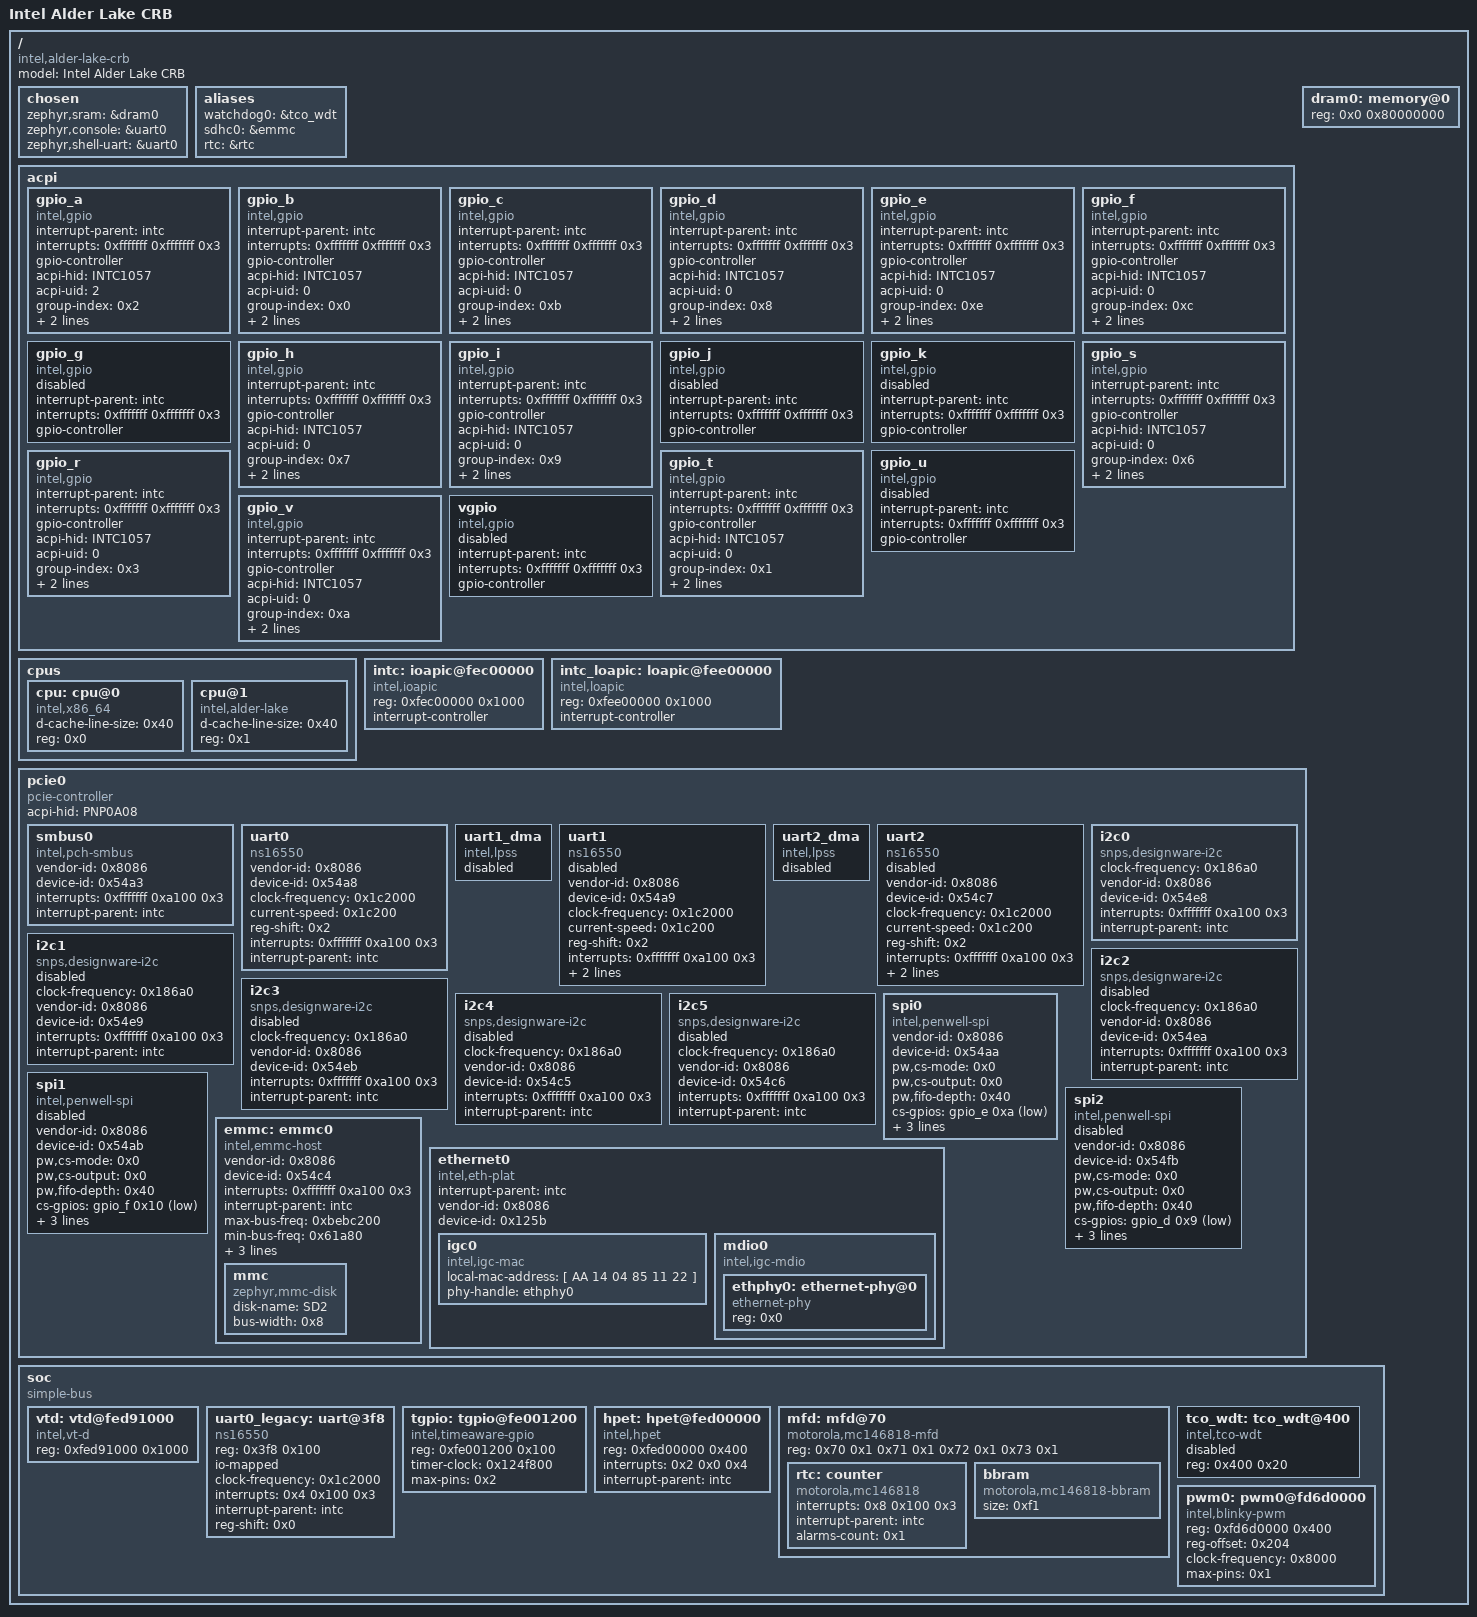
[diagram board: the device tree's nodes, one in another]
/dts-v1/;

/* node '/' defined in zephyr/dts/common/skeleton.dtsi:9 */
/ {
	#address-cells = < 0x1 >;            /* in zephyr/dts/common/skeleton.dtsi:10 */
	#size-cells = < 0x1 >;               /* in zephyr/dts/common/skeleton.dtsi:11 */
	model = "Intel Alder Lake CRB";      /* in zephyr/boards/intel/adl/intel_adl_crb.dts:10 */
	compatible = "intel,alder-lake-crb"; /* in zephyr/boards/intel/adl/intel_adl_crb.dts:11 */

	/* node '/chosen' defined in zephyr/dts/common/skeleton.dtsi:13 */
	chosen {
		zephyr,sram = &dram0;       /* in zephyr/boards/intel/adl/intel_adl.dts:17 */
		zephyr,console = &uart0;    /* in zephyr/boards/intel/adl/intel_adl_crb.dts:14 */
		zephyr,shell-uart = &uart0; /* in zephyr/boards/intel/adl/intel_adl_crb.dts:15 */
	};

	/* node '/aliases' defined in zephyr/dts/common/skeleton.dtsi:15 */
	aliases {
		watchdog0 = &tco_wdt; /* in zephyr/boards/intel/adl/intel_adl.dts:21 */
		sdhc0 = &emmc;        /* in zephyr/boards/intel/adl/intel_adl.dts:22 */
		rtc = &rtc;           /* in zephyr/boards/intel/adl/intel_adl_crb.dts:19 */
	};

	/* node '/acpi' defined in zephyr/dts/x86/intel/gpio_common.dtsi:12 */
	acpi {

		/* node '/acpi/gpio_a' defined in zephyr/dts/x86/intel/gpio_common.dtsi:13 */
		gpio_a: gpio_a {
			compatible = "intel,gpio";                /* in zephyr/dts/x86/intel/gpio_common.dtsi:14 */
			interrupt-parent = < &intc >;             /* in zephyr/dts/x86/intel/gpio_common.dtsi:15 */
			interrupts = < 0xfffffff 0xfffffff 0x3 >; /* in zephyr/dts/x86/intel/gpio_common.dtsi:16 */
			gpio-controller;                          /* in zephyr/dts/x86/intel/gpio_common.dtsi:17 */
			#gpio-cells = < 0x2 >;                    /* in zephyr/dts/x86/intel/gpio_common.dtsi:18 */
			acpi-hid = "INTC1057";                    /* in zephyr/dts/x86/intel/alder_lake.dtsi:57 */
			acpi-uid = "2";                           /* in zephyr/dts/x86/intel/alder_lake.dtsi:58 */
			group-index = < 0x2 >;                    /* in zephyr/dts/x86/intel/alder_lake.dtsi:59 */
			int-stat-offset = < 0x40 >;               /* in zephyr/dts/x86/intel/alder_lake.dtsi:60 */
			int-en-offset = < 0x20 >;                 /* in zephyr/dts/x86/intel/alder_lake.dtsi:61 */
			status = "okay";                          /* in zephyr/dts/x86/intel/alder_lake.dtsi:62 */
		};

		/* node '/acpi/gpio_b' defined in zephyr/dts/x86/intel/gpio_common.dtsi:22 */
		gpio_b: gpio_b {
			compatible = "intel,gpio";                /* in zephyr/dts/x86/intel/gpio_common.dtsi:23 */
			interrupt-parent = < &intc >;             /* in zephyr/dts/x86/intel/gpio_common.dtsi:24 */
			interrupts = < 0xfffffff 0xfffffff 0x3 >; /* in zephyr/dts/x86/intel/gpio_common.dtsi:25 */
			gpio-controller;                          /* in zephyr/dts/x86/intel/gpio_common.dtsi:26 */
			#gpio-cells = < 0x2 >;                    /* in zephyr/dts/x86/intel/gpio_common.dtsi:27 */
			acpi-hid = "INTC1057";                    /* in zephyr/dts/x86/intel/alder_lake.dtsi:66 */
			acpi-uid = "0";                           /* in zephyr/dts/x86/intel/alder_lake.dtsi:67 */
			group-index = < 0x0 >;                    /* in zephyr/dts/x86/intel/alder_lake.dtsi:68 */
			int-stat-offset = < 0x40 >;               /* in zephyr/dts/x86/intel/alder_lake.dtsi:69 */
			int-en-offset = < 0x20 >;                 /* in zephyr/dts/x86/intel/alder_lake.dtsi:70 */
			status = "okay";                          /* in zephyr/dts/x86/intel/alder_lake.dtsi:71 */
		};

		/* node '/acpi/gpio_c' defined in zephyr/dts/x86/intel/gpio_common.dtsi:31 */
		gpio_c: gpio_c {
			compatible = "intel,gpio";                /* in zephyr/dts/x86/intel/gpio_common.dtsi:32 */
			interrupt-parent = < &intc >;             /* in zephyr/dts/x86/intel/gpio_common.dtsi:33 */
			interrupts = < 0xfffffff 0xfffffff 0x3 >; /* in zephyr/dts/x86/intel/gpio_common.dtsi:34 */
			gpio-controller;                          /* in zephyr/dts/x86/intel/gpio_common.dtsi:35 */
			#gpio-cells = < 0x2 >;                    /* in zephyr/dts/x86/intel/gpio_common.dtsi:36 */
			acpi-hid = "INTC1057";                    /* in zephyr/dts/x86/intel/alder_lake.dtsi:75 */
			acpi-uid = "0";                           /* in zephyr/dts/x86/intel/alder_lake.dtsi:76 */
			group-index = < 0xb >;                    /* in zephyr/dts/x86/intel/alder_lake.dtsi:77 */
			int-stat-offset = < 0x40 >;               /* in zephyr/dts/x86/intel/alder_lake.dtsi:78 */
			int-en-offset = < 0x20 >;                 /* in zephyr/dts/x86/intel/alder_lake.dtsi:79 */
			status = "okay";                          /* in zephyr/dts/x86/intel/alder_lake.dtsi:80 */
		};

		/* node '/acpi/gpio_d' defined in zephyr/dts/x86/intel/gpio_common.dtsi:40 */
		gpio_d: gpio_d {
			compatible = "intel,gpio";                /* in zephyr/dts/x86/intel/gpio_common.dtsi:41 */
			interrupt-parent = < &intc >;             /* in zephyr/dts/x86/intel/gpio_common.dtsi:42 */
			interrupts = < 0xfffffff 0xfffffff 0x3 >; /* in zephyr/dts/x86/intel/gpio_common.dtsi:43 */
			gpio-controller;                          /* in zephyr/dts/x86/intel/gpio_common.dtsi:44 */
			#gpio-cells = < 0x2 >;                    /* in zephyr/dts/x86/intel/gpio_common.dtsi:45 */
			acpi-hid = "INTC1057";                    /* in zephyr/dts/x86/intel/alder_lake.dtsi:84 */
			acpi-uid = "0";                           /* in zephyr/dts/x86/intel/alder_lake.dtsi:85 */
			group-index = < 0x8 >;                    /* in zephyr/dts/x86/intel/alder_lake.dtsi:86 */
			int-stat-offset = < 0x40 >;               /* in zephyr/dts/x86/intel/alder_lake.dtsi:87 */
			int-en-offset = < 0x20 >;                 /* in zephyr/dts/x86/intel/alder_lake.dtsi:88 */
			status = "okay";                          /* in zephyr/dts/x86/intel/alder_lake.dtsi:89 */
			phandle = < 0x6 >;                        /* in zephyr/dts/x86/intel/alder_lake.dtsi:359 */
		};

		/* node '/acpi/gpio_e' defined in zephyr/dts/x86/intel/gpio_common.dtsi:49 */
		gpio_e: gpio_e {
			compatible = "intel,gpio";                /* in zephyr/dts/x86/intel/gpio_common.dtsi:50 */
			interrupt-parent = < &intc >;             /* in zephyr/dts/x86/intel/gpio_common.dtsi:51 */
			interrupts = < 0xfffffff 0xfffffff 0x3 >; /* in zephyr/dts/x86/intel/gpio_common.dtsi:52 */
			gpio-controller;                          /* in zephyr/dts/x86/intel/gpio_common.dtsi:53 */
			#gpio-cells = < 0x2 >;                    /* in zephyr/dts/x86/intel/gpio_common.dtsi:54 */
			acpi-hid = "INTC1057";                    /* in zephyr/dts/x86/intel/alder_lake.dtsi:93 */
			acpi-uid = "0";                           /* in zephyr/dts/x86/intel/alder_lake.dtsi:94 */
			group-index = < 0xe >;                    /* in zephyr/dts/x86/intel/alder_lake.dtsi:95 */
			int-stat-offset = < 0x40 >;               /* in zephyr/dts/x86/intel/alder_lake.dtsi:96 */
			int-en-offset = < 0x20 >;                 /* in zephyr/dts/x86/intel/alder_lake.dtsi:97 */
			status = "okay";                          /* in zephyr/dts/x86/intel/alder_lake.dtsi:98 */
			phandle = < 0x4 >;                        /* in zephyr/dts/x86/intel/alder_lake.dtsi:327 */
		};

		/* node '/acpi/gpio_f' defined in zephyr/dts/x86/intel/gpio_common.dtsi:58 */
		gpio_f: gpio_f {
			compatible = "intel,gpio";                /* in zephyr/dts/x86/intel/gpio_common.dtsi:59 */
			interrupt-parent = < &intc >;             /* in zephyr/dts/x86/intel/gpio_common.dtsi:60 */
			interrupts = < 0xfffffff 0xfffffff 0x3 >; /* in zephyr/dts/x86/intel/gpio_common.dtsi:61 */
			gpio-controller;                          /* in zephyr/dts/x86/intel/gpio_common.dtsi:62 */
			#gpio-cells = < 0x2 >;                    /* in zephyr/dts/x86/intel/gpio_common.dtsi:63 */
			acpi-hid = "INTC1057";                    /* in zephyr/dts/x86/intel/alder_lake.dtsi:102 */
			acpi-uid = "0";                           /* in zephyr/dts/x86/intel/alder_lake.dtsi:103 */
			group-index = < 0xc >;                    /* in zephyr/dts/x86/intel/alder_lake.dtsi:104 */
			int-stat-offset = < 0x40 >;               /* in zephyr/dts/x86/intel/alder_lake.dtsi:105 */
			int-en-offset = < 0x20 >;                 /* in zephyr/dts/x86/intel/alder_lake.dtsi:106 */
			status = "okay";                          /* in zephyr/dts/x86/intel/alder_lake.dtsi:107 */
			phandle = < 0x5 >;                        /* in zephyr/dts/x86/intel/alder_lake.dtsi:343 */
		};

		/* node '/acpi/gpio_g' defined in zephyr/dts/x86/intel/gpio_common.dtsi:67 */
		gpio_g: gpio_g {
			compatible = "intel,gpio";                /* in zephyr/dts/x86/intel/gpio_common.dtsi:68 */
			interrupt-parent = < &intc >;             /* in zephyr/dts/x86/intel/gpio_common.dtsi:69 */
			interrupts = < 0xfffffff 0xfffffff 0x3 >; /* in zephyr/dts/x86/intel/gpio_common.dtsi:70 */
			gpio-controller;                          /* in zephyr/dts/x86/intel/gpio_common.dtsi:71 */
			#gpio-cells = < 0x2 >;                    /* in zephyr/dts/x86/intel/gpio_common.dtsi:72 */
			status = "disabled";                      /* in zephyr/dts/x86/intel/gpio_common.dtsi:73 */
		};

		/* node '/acpi/gpio_h' defined in zephyr/dts/x86/intel/gpio_common.dtsi:76 */
		gpio_h: gpio_h {
			compatible = "intel,gpio";                /* in zephyr/dts/x86/intel/gpio_common.dtsi:77 */
			interrupt-parent = < &intc >;             /* in zephyr/dts/x86/intel/gpio_common.dtsi:78 */
			interrupts = < 0xfffffff 0xfffffff 0x3 >; /* in zephyr/dts/x86/intel/gpio_common.dtsi:79 */
			gpio-controller;                          /* in zephyr/dts/x86/intel/gpio_common.dtsi:80 */
			#gpio-cells = < 0x2 >;                    /* in zephyr/dts/x86/intel/gpio_common.dtsi:81 */
			acpi-hid = "INTC1057";                    /* in zephyr/dts/x86/intel/alder_lake.dtsi:111 */
			acpi-uid = "0";                           /* in zephyr/dts/x86/intel/alder_lake.dtsi:112 */
			group-index = < 0x7 >;                    /* in zephyr/dts/x86/intel/alder_lake.dtsi:113 */
			int-stat-offset = < 0x40 >;               /* in zephyr/dts/x86/intel/alder_lake.dtsi:114 */
			int-en-offset = < 0x20 >;                 /* in zephyr/dts/x86/intel/alder_lake.dtsi:115 */
			status = "okay";                          /* in zephyr/dts/x86/intel/alder_lake.dtsi:116 */
		};

		/* node '/acpi/gpio_i' defined in zephyr/dts/x86/intel/gpio_common.dtsi:85 */
		gpio_i: gpio_i {
			compatible = "intel,gpio";                /* in zephyr/dts/x86/intel/gpio_common.dtsi:86 */
			interrupt-parent = < &intc >;             /* in zephyr/dts/x86/intel/gpio_common.dtsi:87 */
			interrupts = < 0xfffffff 0xfffffff 0x3 >; /* in zephyr/dts/x86/intel/gpio_common.dtsi:88 */
			gpio-controller;                          /* in zephyr/dts/x86/intel/gpio_common.dtsi:89 */
			#gpio-cells = < 0x2 >;                    /* in zephyr/dts/x86/intel/gpio_common.dtsi:90 */
			acpi-hid = "INTC1057";                    /* in zephyr/dts/x86/intel/alder_lake.dtsi:120 */
			acpi-uid = "0";                           /* in zephyr/dts/x86/intel/alder_lake.dtsi:121 */
			group-index = < 0x9 >;                    /* in zephyr/dts/x86/intel/alder_lake.dtsi:122 */
			int-stat-offset = < 0x40 >;               /* in zephyr/dts/x86/intel/alder_lake.dtsi:123 */
			int-en-offset = < 0x20 >;                 /* in zephyr/dts/x86/intel/alder_lake.dtsi:124 */
			status = "okay";                          /* in zephyr/dts/x86/intel/alder_lake.dtsi:125 */
		};

		/* node '/acpi/gpio_j' defined in zephyr/dts/x86/intel/gpio_common.dtsi:94 */
		gpio_j: gpio_j {
			compatible = "intel,gpio";                /* in zephyr/dts/x86/intel/gpio_common.dtsi:95 */
			interrupt-parent = < &intc >;             /* in zephyr/dts/x86/intel/gpio_common.dtsi:96 */
			interrupts = < 0xfffffff 0xfffffff 0x3 >; /* in zephyr/dts/x86/intel/gpio_common.dtsi:97 */
			gpio-controller;                          /* in zephyr/dts/x86/intel/gpio_common.dtsi:98 */
			#gpio-cells = < 0x2 >;                    /* in zephyr/dts/x86/intel/gpio_common.dtsi:99 */
			status = "disabled";                      /* in zephyr/dts/x86/intel/gpio_common.dtsi:100 */
		};

		/* node '/acpi/gpio_k' defined in zephyr/dts/x86/intel/gpio_common.dtsi:103 */
		gpio_k: gpio_k {
			compatible = "intel,gpio";                /* in zephyr/dts/x86/intel/gpio_common.dtsi:104 */
			interrupt-parent = < &intc >;             /* in zephyr/dts/x86/intel/gpio_common.dtsi:105 */
			interrupts = < 0xfffffff 0xfffffff 0x3 >; /* in zephyr/dts/x86/intel/gpio_common.dtsi:106 */
			gpio-controller;                          /* in zephyr/dts/x86/intel/gpio_common.dtsi:107 */
			#gpio-cells = < 0x2 >;                    /* in zephyr/dts/x86/intel/gpio_common.dtsi:108 */
			status = "disabled";                      /* in zephyr/dts/x86/intel/gpio_common.dtsi:109 */
		};

		/* node '/acpi/gpio_s' defined in zephyr/dts/x86/intel/gpio_common.dtsi:112 */
		gpio_s: gpio_s {
			compatible = "intel,gpio";                /* in zephyr/dts/x86/intel/gpio_common.dtsi:113 */
			interrupt-parent = < &intc >;             /* in zephyr/dts/x86/intel/gpio_common.dtsi:114 */
			interrupts = < 0xfffffff 0xfffffff 0x3 >; /* in zephyr/dts/x86/intel/gpio_common.dtsi:115 */
			gpio-controller;                          /* in zephyr/dts/x86/intel/gpio_common.dtsi:116 */
			#gpio-cells = < 0x2 >;                    /* in zephyr/dts/x86/intel/gpio_common.dtsi:117 */
			acpi-hid = "INTC1057";                    /* in zephyr/dts/x86/intel/alder_lake.dtsi:129 */
			acpi-uid = "0";                           /* in zephyr/dts/x86/intel/alder_lake.dtsi:130 */
			group-index = < 0x6 >;                    /* in zephyr/dts/x86/intel/alder_lake.dtsi:131 */
			int-stat-offset = < 0x40 >;               /* in zephyr/dts/x86/intel/alder_lake.dtsi:132 */
			int-en-offset = < 0x20 >;                 /* in zephyr/dts/x86/intel/alder_lake.dtsi:133 */
			status = "okay";                          /* in zephyr/dts/x86/intel/alder_lake.dtsi:134 */
		};

		/* node '/acpi/gpio_r' defined in zephyr/dts/x86/intel/gpio_common.dtsi:121 */
		gpio_r: gpio_r {
			compatible = "intel,gpio";                /* in zephyr/dts/x86/intel/gpio_common.dtsi:122 */
			interrupt-parent = < &intc >;             /* in zephyr/dts/x86/intel/gpio_common.dtsi:123 */
			interrupts = < 0xfffffff 0xfffffff 0x3 >; /* in zephyr/dts/x86/intel/gpio_common.dtsi:124 */
			gpio-controller;                          /* in zephyr/dts/x86/intel/gpio_common.dtsi:125 */
			#gpio-cells = < 0x2 >;                    /* in zephyr/dts/x86/intel/gpio_common.dtsi:126 */
			acpi-hid = "INTC1057";                    /* in zephyr/dts/x86/intel/alder_lake.dtsi:138 */
			acpi-uid = "0";                           /* in zephyr/dts/x86/intel/alder_lake.dtsi:139 */
			group-index = < 0x3 >;                    /* in zephyr/dts/x86/intel/alder_lake.dtsi:140 */
			int-stat-offset = < 0x40 >;               /* in zephyr/dts/x86/intel/alder_lake.dtsi:141 */
			int-en-offset = < 0x20 >;                 /* in zephyr/dts/x86/intel/alder_lake.dtsi:142 */
			status = "okay";                          /* in zephyr/dts/x86/intel/alder_lake.dtsi:143 */
		};

		/* node '/acpi/gpio_t' defined in zephyr/dts/x86/intel/gpio_common.dtsi:130 */
		gpio_t: gpio_t {
			compatible = "intel,gpio";                /* in zephyr/dts/x86/intel/gpio_common.dtsi:131 */
			interrupt-parent = < &intc >;             /* in zephyr/dts/x86/intel/gpio_common.dtsi:132 */
			interrupts = < 0xfffffff 0xfffffff 0x3 >; /* in zephyr/dts/x86/intel/gpio_common.dtsi:133 */
			gpio-controller;                          /* in zephyr/dts/x86/intel/gpio_common.dtsi:134 */
			#gpio-cells = < 0x2 >;                    /* in zephyr/dts/x86/intel/gpio_common.dtsi:135 */
			acpi-hid = "INTC1057";                    /* in zephyr/dts/x86/intel/alder_lake.dtsi:147 */
			acpi-uid = "0";                           /* in zephyr/dts/x86/intel/alder_lake.dtsi:148 */
			group-index = < 0x1 >;                    /* in zephyr/dts/x86/intel/alder_lake.dtsi:149 */
			int-stat-offset = < 0x40 >;               /* in zephyr/dts/x86/intel/alder_lake.dtsi:150 */
			int-en-offset = < 0x20 >;                 /* in zephyr/dts/x86/intel/alder_lake.dtsi:151 */
			status = "okay";                          /* in zephyr/dts/x86/intel/alder_lake.dtsi:152 */
		};

		/* node '/acpi/gpio_u' defined in zephyr/dts/x86/intel/gpio_common.dtsi:139 */
		gpio_u: gpio_u {
			compatible = "intel,gpio";                /* in zephyr/dts/x86/intel/gpio_common.dtsi:140 */
			interrupt-parent = < &intc >;             /* in zephyr/dts/x86/intel/gpio_common.dtsi:141 */
			interrupts = < 0xfffffff 0xfffffff 0x3 >; /* in zephyr/dts/x86/intel/gpio_common.dtsi:142 */
			gpio-controller;                          /* in zephyr/dts/x86/intel/gpio_common.dtsi:143 */
			#gpio-cells = < 0x2 >;                    /* in zephyr/dts/x86/intel/gpio_common.dtsi:144 */
			status = "disabled";                      /* in zephyr/dts/x86/intel/gpio_common.dtsi:145 */
		};

		/* node '/acpi/gpio_v' defined in zephyr/dts/x86/intel/gpio_common.dtsi:148 */
		gpio_v: gpio_v {
			compatible = "intel,gpio";                /* in zephyr/dts/x86/intel/gpio_common.dtsi:149 */
			interrupt-parent = < &intc >;             /* in zephyr/dts/x86/intel/gpio_common.dtsi:150 */
			interrupts = < 0xfffffff 0xfffffff 0x3 >; /* in zephyr/dts/x86/intel/gpio_common.dtsi:151 */
			gpio-controller;                          /* in zephyr/dts/x86/intel/gpio_common.dtsi:152 */
			#gpio-cells = < 0x2 >;                    /* in zephyr/dts/x86/intel/gpio_common.dtsi:153 */
			acpi-hid = "INTC1057";                    /* in zephyr/dts/x86/intel/alder_lake.dtsi:156 */
			acpi-uid = "0";                           /* in zephyr/dts/x86/intel/alder_lake.dtsi:157 */
			group-index = < 0xa >;                    /* in zephyr/dts/x86/intel/alder_lake.dtsi:158 */
			int-stat-offset = < 0x40 >;               /* in zephyr/dts/x86/intel/alder_lake.dtsi:159 */
			int-en-offset = < 0x20 >;                 /* in zephyr/dts/x86/intel/alder_lake.dtsi:160 */
			status = "okay";                          /* in zephyr/dts/x86/intel/alder_lake.dtsi:161 */
		};

		/* node '/acpi/vgpio' defined in zephyr/dts/x86/intel/gpio_common.dtsi:157 */
		vgpio: vgpio {
			compatible = "intel,gpio";                /* in zephyr/dts/x86/intel/gpio_common.dtsi:158 */
			interrupt-parent = < &intc >;             /* in zephyr/dts/x86/intel/gpio_common.dtsi:159 */
			interrupts = < 0xfffffff 0xfffffff 0x3 >; /* in zephyr/dts/x86/intel/gpio_common.dtsi:160 */
			gpio-controller;                          /* in zephyr/dts/x86/intel/gpio_common.dtsi:161 */
			#gpio-cells = < 0x2 >;                    /* in zephyr/dts/x86/intel/gpio_common.dtsi:162 */
			status = "disabled";                      /* in zephyr/dts/x86/intel/gpio_common.dtsi:163 */
		};
	};

	/* node '/cpus' defined in zephyr/dts/x86/intel/alder_lake.dtsi:15 */
	cpus {
		#address-cells = < 0x1 >; /* in zephyr/dts/x86/intel/alder_lake.dtsi:16 */
		#size-cells = < 0x0 >;    /* in zephyr/dts/x86/intel/alder_lake.dtsi:17 */

		/* node '/cpus/cpu@0' defined in zephyr/dts/x86/intel/alder_lake.dtsi:19 */
		cpu: cpu@0 {
			device_type = "cpu";          /* in zephyr/dts/x86/intel/alder_lake.dtsi:20 */
			d-cache-line-size = < 0x40 >; /* in zephyr/dts/x86/intel/alder_lake.dtsi:22 */
			reg = < 0x0 >;                /* in zephyr/dts/x86/intel/alder_lake.dtsi:23 */
			compatible = "intel,x86_64";  /* in zephyr/boards/intel/adl/intel_adl.dts:27 */
		};

		/* node '/cpus/cpu@1' defined in zephyr/dts/x86/intel/alder_lake.dtsi:26 */
		cpu@1 {
			device_type = "cpu";             /* in zephyr/dts/x86/intel/alder_lake.dtsi:27 */
			compatible = "intel,alder-lake",
			             "intel,x86_64";     /* in zephyr/dts/x86/intel/alder_lake.dtsi:28 */
			d-cache-line-size = < 0x40 >;    /* in zephyr/dts/x86/intel/alder_lake.dtsi:29 */
			reg = < 0x1 >;                   /* in zephyr/dts/x86/intel/alder_lake.dtsi:30 */
		};
	};

	/* node '/memory@0' defined in zephyr/dts/x86/intel/alder_lake.dtsi:34 */
	dram0: memory@0 {
		device_type = "memory";   /* in zephyr/dts/x86/intel/alder_lake.dtsi:35 */
		reg = < 0x0 0x80000000 >; /* in zephyr/dts/x86/intel/alder_lake.dtsi:36 */
	};

	/* node '/ioapic@fec00000' defined in zephyr/dts/x86/intel/alder_lake.dtsi:39 */
	intc: ioapic@fec00000 {
		compatible = "intel,ioapic"; /* in zephyr/dts/x86/intel/alder_lake.dtsi:40 */
		#address-cells = < 0x1 >;    /* in zephyr/dts/x86/intel/alder_lake.dtsi:41 */
		#interrupt-cells = < 0x3 >;  /* in zephyr/dts/x86/intel/alder_lake.dtsi:42 */
		reg = < 0xfec00000 0x1000 >; /* in zephyr/dts/x86/intel/alder_lake.dtsi:43 */
		interrupt-controller;        /* in zephyr/dts/x86/intel/alder_lake.dtsi:44 */
		phandle = < 0x1 >;           /* in zephyr/dts/x86/intel/gpio_common.dtsi:15 */
	};

	/* node '/loapic@fee00000' defined in zephyr/dts/x86/intel/alder_lake.dtsi:47 */
	intc_loapic: loapic@fee00000 {
		compatible = "intel,loapic"; /* in zephyr/dts/x86/intel/alder_lake.dtsi:48 */
		reg = < 0xfee00000 0x1000 >; /* in zephyr/dts/x86/intel/alder_lake.dtsi:49 */
		interrupt-controller;        /* in zephyr/dts/x86/intel/alder_lake.dtsi:50 */
		#interrupt-cells = < 0x3 >;  /* in zephyr/dts/x86/intel/alder_lake.dtsi:51 */
		#address-cells = < 0x1 >;    /* in zephyr/dts/x86/intel/alder_lake.dtsi:52 */
	};

	/* node '/pcie0' defined in zephyr/dts/x86/intel/alder_lake.dtsi:165 */
	pcie0: pcie0 {
		#address-cells = < 0x1 >;       /* in zephyr/dts/x86/intel/alder_lake.dtsi:166 */
		#size-cells = < 0x1 >;          /* in zephyr/dts/x86/intel/alder_lake.dtsi:167 */
		compatible = "pcie-controller"; /* in zephyr/dts/x86/intel/alder_lake.dtsi:168 */
		acpi-hid = "PNP0A08";           /* in zephyr/dts/x86/intel/alder_lake.dtsi:169 */
		ranges;                         /* in zephyr/dts/x86/intel/alder_lake.dtsi:170 */

		/* node '/pcie0/smbus0' defined in zephyr/dts/x86/intel/alder_lake.dtsi:172 */
		smbus0: smbus0 {
			compatible = "intel,pch-smbus";        /* in zephyr/dts/x86/intel/alder_lake.dtsi:173 */
			#address-cells = < 0x1 >;              /* in zephyr/dts/x86/intel/alder_lake.dtsi:174 */
			#size-cells = < 0x0 >;                 /* in zephyr/dts/x86/intel/alder_lake.dtsi:175 */
			vendor-id = < 0x8086 >;                /* in zephyr/dts/x86/intel/alder_lake.dtsi:176 */
			device-id = < 0x54a3 >;                /* in zephyr/dts/x86/intel/alder_lake.dtsi:177 */
			interrupts = < 0xfffffff 0xa100 0x3 >; /* in zephyr/dts/x86/intel/alder_lake.dtsi:178 */
			interrupt-parent = < &intc >;          /* in zephyr/dts/x86/intel/alder_lake.dtsi:179 */
			status = "okay";                       /* in zephyr/dts/x86/intel/alder_lake.dtsi:181 */
		};

		/* node '/pcie0/uart0' defined in zephyr/dts/x86/intel/alder_lake.dtsi:184 */
		uart0: uart0 {
			compatible = "ns16550";                /* in zephyr/dts/x86/intel/alder_lake.dtsi:185 */
			vendor-id = < 0x8086 >;                /* in zephyr/dts/x86/intel/alder_lake.dtsi:187 */
			device-id = < 0x54a8 >;                /* in zephyr/dts/x86/intel/alder_lake.dtsi:188 */
			clock-frequency = < 0x1c2000 >;        /* in zephyr/dts/x86/intel/alder_lake.dtsi:190 */
			current-speed = < 0x1c200 >;           /* in zephyr/dts/x86/intel/alder_lake.dtsi:191 */
			reg-shift = < 0x2 >;                   /* in zephyr/dts/x86/intel/alder_lake.dtsi:192 */
			interrupts = < 0xfffffff 0xa100 0x3 >; /* in zephyr/dts/x86/intel/alder_lake.dtsi:194 */
			interrupt-parent = < &intc >;          /* in zephyr/dts/x86/intel/alder_lake.dtsi:195 */
			status = "okay";                       /* in zephyr/boards/intel/adl/intel_adl_crb.dts:24 */
		};

		/* node '/pcie0/uart1_dma' defined in zephyr/dts/x86/intel/alder_lake.dtsi:199 */
		uart1_dma: uart1_dma {
			compatible = "intel,lpss"; /* in zephyr/dts/x86/intel/alder_lake.dtsi:200 */
			#dma-cells = < 0x1 >;      /* in zephyr/dts/x86/intel/alder_lake.dtsi:201 */
			status = "disabled";       /* in zephyr/dts/x86/intel/alder_lake.dtsi:202 */
			phandle = < 0x2 >;         /* in zephyr/dts/x86/intel/alder_lake.dtsi:214 */
		};

		/* node '/pcie0/uart1' defined in zephyr/dts/x86/intel/alder_lake.dtsi:205 */
		uart1: uart1 {
			compatible = "ns16550";                /* in zephyr/dts/x86/intel/alder_lake.dtsi:206 */
			vendor-id = < 0x8086 >;                /* in zephyr/dts/x86/intel/alder_lake.dtsi:207 */
			device-id = < 0x54a9 >;                /* in zephyr/dts/x86/intel/alder_lake.dtsi:208 */
			clock-frequency = < 0x1c2000 >;        /* in zephyr/dts/x86/intel/alder_lake.dtsi:209 */
			current-speed = < 0x1c200 >;           /* in zephyr/dts/x86/intel/alder_lake.dtsi:210 */
			reg-shift = < 0x2 >;                   /* in zephyr/dts/x86/intel/alder_lake.dtsi:211 */
			interrupts = < 0xfffffff 0xa100 0x3 >; /* in zephyr/dts/x86/intel/alder_lake.dtsi:212 */
			interrupt-parent = < &intc >;          /* in zephyr/dts/x86/intel/alder_lake.dtsi:213 */
			dmas = < &uart1_dma 0x0 >,
			       < &uart1_dma 0x1 >;             /* in zephyr/dts/x86/intel/alder_lake.dtsi:214 */
			dma-names = "tx",
			            "rx";                      /* in zephyr/dts/x86/intel/alder_lake.dtsi:215 */
			status = "disabled";                   /* in zephyr/dts/x86/intel/alder_lake.dtsi:216 */
		};

		/* node '/pcie0/uart2_dma' defined in zephyr/dts/x86/intel/alder_lake.dtsi:219 */
		uart2_dma: uart2_dma {
			compatible = "intel,lpss"; /* in zephyr/dts/x86/intel/alder_lake.dtsi:220 */
			#dma-cells = < 0x1 >;      /* in zephyr/dts/x86/intel/alder_lake.dtsi:221 */
			status = "disabled";       /* in zephyr/dts/x86/intel/alder_lake.dtsi:222 */
			phandle = < 0x3 >;         /* in zephyr/dts/x86/intel/alder_lake.dtsi:234 */
		};

		/* node '/pcie0/uart2' defined in zephyr/dts/x86/intel/alder_lake.dtsi:225 */
		uart2: uart2 {
			compatible = "ns16550";                /* in zephyr/dts/x86/intel/alder_lake.dtsi:226 */
			vendor-id = < 0x8086 >;                /* in zephyr/dts/x86/intel/alder_lake.dtsi:227 */
			device-id = < 0x54c7 >;                /* in zephyr/dts/x86/intel/alder_lake.dtsi:228 */
			clock-frequency = < 0x1c2000 >;        /* in zephyr/dts/x86/intel/alder_lake.dtsi:229 */
			current-speed = < 0x1c200 >;           /* in zephyr/dts/x86/intel/alder_lake.dtsi:230 */
			reg-shift = < 0x2 >;                   /* in zephyr/dts/x86/intel/alder_lake.dtsi:231 */
			interrupts = < 0xfffffff 0xa100 0x3 >; /* in zephyr/dts/x86/intel/alder_lake.dtsi:232 */
			interrupt-parent = < &intc >;          /* in zephyr/dts/x86/intel/alder_lake.dtsi:233 */
			dmas = < &uart2_dma 0x0 >,
			       < &uart2_dma 0x1 >;             /* in zephyr/dts/x86/intel/alder_lake.dtsi:234 */
			dma-names = "tx",
			            "rx";                      /* in zephyr/dts/x86/intel/alder_lake.dtsi:235 */
			status = "disabled";                   /* in zephyr/dts/x86/intel/alder_lake.dtsi:237 */
		};

		/* node '/pcie0/i2c0' defined in zephyr/dts/x86/intel/alder_lake.dtsi:240 */
		i2c0: i2c0 {
			compatible = "snps,designware-i2c";    /* in zephyr/dts/x86/intel/alder_lake.dtsi:241 */
			clock-frequency = < 0x186a0 >;         /* in zephyr/dts/x86/intel/alder_lake.dtsi:242 */
			#address-cells = < 0x1 >;              /* in zephyr/dts/x86/intel/alder_lake.dtsi:243 */
			#size-cells = < 0x0 >;                 /* in zephyr/dts/x86/intel/alder_lake.dtsi:244 */
			vendor-id = < 0x8086 >;                /* in zephyr/dts/x86/intel/alder_lake.dtsi:245 */
			device-id = < 0x54e8 >;                /* in zephyr/dts/x86/intel/alder_lake.dtsi:246 */
			interrupts = < 0xfffffff 0xa100 0x3 >; /* in zephyr/dts/x86/intel/alder_lake.dtsi:247 */
			interrupt-parent = < &intc >;          /* in zephyr/dts/x86/intel/alder_lake.dtsi:248 */
			status = "okay";                       /* in zephyr/dts/x86/intel/alder_lake.dtsi:250 */
		};

		/* node '/pcie0/i2c1' defined in zephyr/dts/x86/intel/alder_lake.dtsi:253 */
		i2c1: i2c1 {
			compatible = "snps,designware-i2c";    /* in zephyr/dts/x86/intel/alder_lake.dtsi:254 */
			clock-frequency = < 0x186a0 >;         /* in zephyr/dts/x86/intel/alder_lake.dtsi:255 */
			#address-cells = < 0x1 >;              /* in zephyr/dts/x86/intel/alder_lake.dtsi:256 */
			#size-cells = < 0x0 >;                 /* in zephyr/dts/x86/intel/alder_lake.dtsi:257 */
			vendor-id = < 0x8086 >;                /* in zephyr/dts/x86/intel/alder_lake.dtsi:258 */
			device-id = < 0x54e9 >;                /* in zephyr/dts/x86/intel/alder_lake.dtsi:259 */
			interrupts = < 0xfffffff 0xa100 0x3 >; /* in zephyr/dts/x86/intel/alder_lake.dtsi:260 */
			interrupt-parent = < &intc >;          /* in zephyr/dts/x86/intel/alder_lake.dtsi:261 */
			status = "disabled";                   /* in zephyr/dts/x86/intel/alder_lake.dtsi:263 */
		};

		/* node '/pcie0/i2c2' defined in zephyr/dts/x86/intel/alder_lake.dtsi:266 */
		i2c2: i2c2 {
			compatible = "snps,designware-i2c";    /* in zephyr/dts/x86/intel/alder_lake.dtsi:267 */
			clock-frequency = < 0x186a0 >;         /* in zephyr/dts/x86/intel/alder_lake.dtsi:268 */
			#address-cells = < 0x1 >;              /* in zephyr/dts/x86/intel/alder_lake.dtsi:269 */
			#size-cells = < 0x0 >;                 /* in zephyr/dts/x86/intel/alder_lake.dtsi:270 */
			vendor-id = < 0x8086 >;                /* in zephyr/dts/x86/intel/alder_lake.dtsi:271 */
			device-id = < 0x54ea >;                /* in zephyr/dts/x86/intel/alder_lake.dtsi:272 */
			interrupts = < 0xfffffff 0xa100 0x3 >; /* in zephyr/dts/x86/intel/alder_lake.dtsi:273 */
			interrupt-parent = < &intc >;          /* in zephyr/dts/x86/intel/alder_lake.dtsi:274 */
			status = "disabled";                   /* in zephyr/dts/x86/intel/alder_lake.dtsi:276 */
		};

		/* node '/pcie0/i2c3' defined in zephyr/dts/x86/intel/alder_lake.dtsi:279 */
		i2c3: i2c3 {
			compatible = "snps,designware-i2c";    /* in zephyr/dts/x86/intel/alder_lake.dtsi:280 */
			clock-frequency = < 0x186a0 >;         /* in zephyr/dts/x86/intel/alder_lake.dtsi:281 */
			#address-cells = < 0x1 >;              /* in zephyr/dts/x86/intel/alder_lake.dtsi:282 */
			#size-cells = < 0x0 >;                 /* in zephyr/dts/x86/intel/alder_lake.dtsi:283 */
			vendor-id = < 0x8086 >;                /* in zephyr/dts/x86/intel/alder_lake.dtsi:284 */
			device-id = < 0x54eb >;                /* in zephyr/dts/x86/intel/alder_lake.dtsi:285 */
			interrupts = < 0xfffffff 0xa100 0x3 >; /* in zephyr/dts/x86/intel/alder_lake.dtsi:286 */
			interrupt-parent = < &intc >;          /* in zephyr/dts/x86/intel/alder_lake.dtsi:287 */
			status = "disabled";                   /* in zephyr/dts/x86/intel/alder_lake.dtsi:289 */
		};

		/* node '/pcie0/i2c4' defined in zephyr/dts/x86/intel/alder_lake.dtsi:292 */
		i2c4: i2c4 {
			compatible = "snps,designware-i2c";    /* in zephyr/dts/x86/intel/alder_lake.dtsi:293 */
			clock-frequency = < 0x186a0 >;         /* in zephyr/dts/x86/intel/alder_lake.dtsi:294 */
			#address-cells = < 0x1 >;              /* in zephyr/dts/x86/intel/alder_lake.dtsi:295 */
			#size-cells = < 0x0 >;                 /* in zephyr/dts/x86/intel/alder_lake.dtsi:296 */
			vendor-id = < 0x8086 >;                /* in zephyr/dts/x86/intel/alder_lake.dtsi:297 */
			device-id = < 0x54c5 >;                /* in zephyr/dts/x86/intel/alder_lake.dtsi:298 */
			interrupts = < 0xfffffff 0xa100 0x3 >; /* in zephyr/dts/x86/intel/alder_lake.dtsi:299 */
			interrupt-parent = < &intc >;          /* in zephyr/dts/x86/intel/alder_lake.dtsi:300 */
			status = "disabled";                   /* in zephyr/dts/x86/intel/alder_lake.dtsi:302 */
		};

		/* node '/pcie0/i2c5' defined in zephyr/dts/x86/intel/alder_lake.dtsi:305 */
		i2c5: i2c5 {
			compatible = "snps,designware-i2c";    /* in zephyr/dts/x86/intel/alder_lake.dtsi:306 */
			clock-frequency = < 0x186a0 >;         /* in zephyr/dts/x86/intel/alder_lake.dtsi:307 */
			#address-cells = < 0x1 >;              /* in zephyr/dts/x86/intel/alder_lake.dtsi:308 */
			#size-cells = < 0x0 >;                 /* in zephyr/dts/x86/intel/alder_lake.dtsi:309 */
			vendor-id = < 0x8086 >;                /* in zephyr/dts/x86/intel/alder_lake.dtsi:310 */
			device-id = < 0x54c6 >;                /* in zephyr/dts/x86/intel/alder_lake.dtsi:311 */
			interrupts = < 0xfffffff 0xa100 0x3 >; /* in zephyr/dts/x86/intel/alder_lake.dtsi:312 */
			interrupt-parent = < &intc >;          /* in zephyr/dts/x86/intel/alder_lake.dtsi:313 */
			status = "disabled";                   /* in zephyr/dts/x86/intel/alder_lake.dtsi:315 */
		};

		/* node '/pcie0/spi0' defined in zephyr/dts/x86/intel/alder_lake.dtsi:318 */
		spi0: spi0 {
			compatible = "intel,penwell-spi";      /* in zephyr/dts/x86/intel/alder_lake.dtsi:319 */
			vendor-id = < 0x8086 >;                /* in zephyr/dts/x86/intel/alder_lake.dtsi:320 */
			device-id = < 0x54aa >;                /* in zephyr/dts/x86/intel/alder_lake.dtsi:321 */
			#address-cells = < 0x1 >;              /* in zephyr/dts/x86/intel/alder_lake.dtsi:322 */
			#size-cells = < 0x0 >;                 /* in zephyr/dts/x86/intel/alder_lake.dtsi:323 */
			pw,cs-mode = < 0x0 >;                  /* in zephyr/dts/x86/intel/alder_lake.dtsi:324 */
			pw,cs-output = < 0x0 >;                /* in zephyr/dts/x86/intel/alder_lake.dtsi:325 */
			pw,fifo-depth = < 0x40 >;              /* in zephyr/dts/x86/intel/alder_lake.dtsi:326 */
			cs-gpios = < &gpio_e 0xa 0x1 >;        /* in zephyr/dts/x86/intel/alder_lake.dtsi:327 */
			clock-frequency = < 0x5f5e100 >;       /* in zephyr/dts/x86/intel/alder_lake.dtsi:328 */
			interrupts = < 0xfffffff 0xa100 0x3 >; /* in zephyr/dts/x86/intel/alder_lake.dtsi:329 */
			interrupt-parent = < &intc >;          /* in zephyr/dts/x86/intel/alder_lake.dtsi:330 */
			status = "okay";                       /* in zephyr/dts/x86/intel/alder_lake.dtsi:331 */
		};

		/* node '/pcie0/spi1' defined in zephyr/dts/x86/intel/alder_lake.dtsi:334 */
		spi1: spi1 {
			compatible = "intel,penwell-spi";      /* in zephyr/dts/x86/intel/alder_lake.dtsi:335 */
			vendor-id = < 0x8086 >;                /* in zephyr/dts/x86/intel/alder_lake.dtsi:336 */
			device-id = < 0x54ab >;                /* in zephyr/dts/x86/intel/alder_lake.dtsi:337 */
			#address-cells = < 0x1 >;              /* in zephyr/dts/x86/intel/alder_lake.dtsi:338 */
			#size-cells = < 0x0 >;                 /* in zephyr/dts/x86/intel/alder_lake.dtsi:339 */
			pw,cs-mode = < 0x0 >;                  /* in zephyr/dts/x86/intel/alder_lake.dtsi:340 */
			pw,cs-output = < 0x0 >;                /* in zephyr/dts/x86/intel/alder_lake.dtsi:341 */
			pw,fifo-depth = < 0x40 >;              /* in zephyr/dts/x86/intel/alder_lake.dtsi:342 */
			cs-gpios = < &gpio_f 0x10 0x1 >;       /* in zephyr/dts/x86/intel/alder_lake.dtsi:343 */
			clock-frequency = < 0x5f5e100 >;       /* in zephyr/dts/x86/intel/alder_lake.dtsi:344 */
			interrupts = < 0xfffffff 0xa100 0x3 >; /* in zephyr/dts/x86/intel/alder_lake.dtsi:345 */
			interrupt-parent = < &intc >;          /* in zephyr/dts/x86/intel/alder_lake.dtsi:346 */
			status = "disabled";                   /* in zephyr/dts/x86/intel/alder_lake.dtsi:347 */
		};

		/* node '/pcie0/spi2' defined in zephyr/dts/x86/intel/alder_lake.dtsi:350 */
		spi2: spi2 {
			compatible = "intel,penwell-spi";      /* in zephyr/dts/x86/intel/alder_lake.dtsi:351 */
			vendor-id = < 0x8086 >;                /* in zephyr/dts/x86/intel/alder_lake.dtsi:352 */
			device-id = < 0x54fb >;                /* in zephyr/dts/x86/intel/alder_lake.dtsi:353 */
			#address-cells = < 0x1 >;              /* in zephyr/dts/x86/intel/alder_lake.dtsi:354 */
			#size-cells = < 0x0 >;                 /* in zephyr/dts/x86/intel/alder_lake.dtsi:355 */
			pw,cs-mode = < 0x0 >;                  /* in zephyr/dts/x86/intel/alder_lake.dtsi:356 */
			pw,cs-output = < 0x0 >;                /* in zephyr/dts/x86/intel/alder_lake.dtsi:357 */
			pw,fifo-depth = < 0x40 >;              /* in zephyr/dts/x86/intel/alder_lake.dtsi:358 */
			cs-gpios = < &gpio_d 0x9 0x1 >;        /* in zephyr/dts/x86/intel/alder_lake.dtsi:359 */
			clock-frequency = < 0x5f5e100 >;       /* in zephyr/dts/x86/intel/alder_lake.dtsi:360 */
			interrupts = < 0xfffffff 0xa100 0x3 >; /* in zephyr/dts/x86/intel/alder_lake.dtsi:361 */
			interrupt-parent = < &intc >;          /* in zephyr/dts/x86/intel/alder_lake.dtsi:362 */
			status = "disabled";                   /* in zephyr/dts/x86/intel/alder_lake.dtsi:363 */
		};

		/* node '/pcie0/emmc0' defined in zephyr/dts/x86/intel/alder_lake.dtsi:366 */
		emmc: emmc0 {
			compatible = "intel,emmc-host";        /* in zephyr/dts/x86/intel/alder_lake.dtsi:367 */
			vendor-id = < 0x8086 >;                /* in zephyr/dts/x86/intel/alder_lake.dtsi:368 */
			device-id = < 0x54c4 >;                /* in zephyr/dts/x86/intel/alder_lake.dtsi:369 */
			interrupts = < 0xfffffff 0xa100 0x3 >; /* in zephyr/dts/x86/intel/alder_lake.dtsi:370 */
			interrupt-parent = < &intc >;          /* in zephyr/dts/x86/intel/alder_lake.dtsi:371 */
			max-bus-freq = < 0xbebc200 >;          /* in zephyr/dts/x86/intel/alder_lake.dtsi:373 */
			min-bus-freq = < 0x61a80 >;            /* in zephyr/dts/x86/intel/alder_lake.dtsi:374 */
			power-delay-ms = < 0x1f4 >;            /* in zephyr/dts/x86/intel/alder_lake.dtsi:375 */
			mmc-hs400-1_8v;                        /* in zephyr/dts/x86/intel/alder_lake.dtsi:376 */
			mmc-hs200-1_8v;                        /* in zephyr/dts/x86/intel/alder_lake.dtsi:377 */
			status = "okay";                       /* in zephyr/dts/x86/intel/alder_lake.dtsi:386 */

			/* node '/pcie0/emmc0/mmc' defined in zephyr/dts/x86/intel/alder_lake.dtsi:379 */
			mmc {
				compatible = "zephyr,mmc-disk"; /* in zephyr/dts/x86/intel/alder_lake.dtsi:380 */
				disk-name = "SD2";              /* in zephyr/dts/x86/intel/alder_lake.dtsi:381 */
				bus-width = < 0x8 >;            /* in zephyr/dts/x86/intel/alder_lake.dtsi:382 */
				status = "okay";                /* in zephyr/dts/x86/intel/alder_lake.dtsi:383 */
			};
		};

		/* node '/pcie0/ethernet0' defined in zephyr/dts/x86/intel/alder_lake.dtsi:389 */
		ethernet0: ethernet0 {
			compatible = "intel,eth-plat"; /* in zephyr/dts/x86/intel/alder_lake.dtsi:390 */
			interrupt-parent = < &intc >;  /* in zephyr/dts/x86/intel/alder_lake.dtsi:391 */
			vendor-id = < 0x8086 >;        /* in zephyr/dts/x86/intel/alder_lake.dtsi:392 */
			device-id = < 0x125b >;        /* in zephyr/dts/x86/intel/alder_lake.dtsi:393 */

			/* node '/pcie0/ethernet0/igc0' defined in zephyr/dts/x86/intel/alder_lake.dtsi:395 */
			igc0: igc0 {
				compatible = "intel,igc-mac";              /* in zephyr/dts/x86/intel/alder_lake.dtsi:396 */
				local-mac-address = [ AA 14 04 85 11 22 ]; /* in zephyr/dts/x86/intel/alder_lake.dtsi:397 */
				phy-handle = < &ethphy0 >;                 /* in zephyr/dts/x86/intel/alder_lake.dtsi:398 */
				status = "okay";                           /* in zephyr/dts/x86/intel/alder_lake.dtsi:399 */
			};

			/* node '/pcie0/ethernet0/mdio0' defined in zephyr/dts/x86/intel/alder_lake.dtsi:402 */
			mdio0: mdio0 {
				compatible = "intel,igc-mdio"; /* in zephyr/dts/x86/intel/alder_lake.dtsi:403 */
				#address-cells = < 0x1 >;      /* in zephyr/dts/x86/intel/alder_lake.dtsi:404 */
				#size-cells = < 0x0 >;         /* in zephyr/dts/x86/intel/alder_lake.dtsi:405 */
				status = "okay";               /* in zephyr/dts/x86/intel/alder_lake.dtsi:406 */

				/* node '/pcie0/ethernet0/mdio0/ethernet-phy@0' defined in zephyr/dts/x86/intel/alder_lake.dtsi:408 */
				ethphy0: ethernet-phy@0 {
					compatible = "ethernet-phy"; /* in zephyr/dts/x86/intel/alder_lake.dtsi:409 */
					reg = < 0x0 >;               /* in zephyr/dts/x86/intel/alder_lake.dtsi:410 */
					status = "okay";             /* in zephyr/dts/x86/intel/alder_lake.dtsi:411 */
					phandle = < 0x7 >;           /* in zephyr/dts/x86/intel/alder_lake.dtsi:398 */
				};
			};
		};
	};

	/* node '/soc' defined in zephyr/dts/x86/intel/alder_lake.dtsi:417 */
	soc {
		#address-cells = < 0x1 >;  /* in zephyr/dts/x86/intel/alder_lake.dtsi:418 */
		#size-cells = < 0x1 >;     /* in zephyr/dts/x86/intel/alder_lake.dtsi:419 */
		compatible = "simple-bus"; /* in zephyr/dts/x86/intel/alder_lake.dtsi:420 */
		ranges;                    /* in zephyr/dts/x86/intel/alder_lake.dtsi:421 */

		/* node '/soc/vtd@fed91000' defined in zephyr/dts/x86/intel/alder_lake.dtsi:423 */
		vtd: vtd@fed91000 {
			compatible = "intel,vt-d";   /* in zephyr/dts/x86/intel/alder_lake.dtsi:424 */
			reg = < 0xfed91000 0x1000 >; /* in zephyr/dts/x86/intel/alder_lake.dtsi:425 */
			status = "okay";             /* in zephyr/dts/x86/intel/alder_lake.dtsi:426 */
		};

		/* node '/soc/uart@3f8' defined in zephyr/dts/x86/intel/alder_lake.dtsi:429 */
		uart0_legacy: uart@3f8 {
			compatible = "ns16550";         /* in zephyr/dts/x86/intel/alder_lake.dtsi:430 */
			reg = < 0x3f8 0x100 >;          /* in zephyr/dts/x86/intel/alder_lake.dtsi:431 */
			io-mapped;                      /* in zephyr/dts/x86/intel/alder_lake.dtsi:432 */
			clock-frequency = < 0x1c2000 >; /* in zephyr/dts/x86/intel/alder_lake.dtsi:433 */
			interrupts = < 0x4 0x100 0x3 >; /* in zephyr/dts/x86/intel/alder_lake.dtsi:434 */
			interrupt-parent = < &intc >;   /* in zephyr/dts/x86/intel/alder_lake.dtsi:435 */
			reg-shift = < 0x0 >;            /* in zephyr/dts/x86/intel/alder_lake.dtsi:436 */
			status = "okay";                /* in zephyr/dts/x86/intel/alder_lake.dtsi:437 */
		};

		/* node '/soc/tgpio@fe001200' defined in zephyr/dts/x86/intel/alder_lake.dtsi:440 */
		tgpio: tgpio@fe001200 {
			compatible = "intel,timeaware-gpio"; /* in zephyr/dts/x86/intel/alder_lake.dtsi:441 */
			reg = < 0xfe001200 0x100 >;          /* in zephyr/dts/x86/intel/alder_lake.dtsi:442 */
			timer-clock = < 0x124f800 >;         /* in zephyr/dts/x86/intel/alder_lake.dtsi:443 */
			max-pins = < 0x2 >;                  /* in zephyr/dts/x86/intel/alder_lake.dtsi:444 */
			status = "okay";                     /* in zephyr/dts/x86/intel/alder_lake.dtsi:445 */
		};

		/* node '/soc/hpet@fed00000' defined in zephyr/dts/x86/intel/alder_lake.dtsi:448 */
		hpet: hpet@fed00000 {
			compatible = "intel,hpet";    /* in zephyr/dts/x86/intel/alder_lake.dtsi:449 */
			reg = < 0xfed00000 0x400 >;   /* in zephyr/dts/x86/intel/alder_lake.dtsi:450 */
			interrupts = < 0x2 0x0 0x4 >; /* in zephyr/dts/x86/intel/alder_lake.dtsi:451 */
			interrupt-parent = < &intc >; /* in zephyr/dts/x86/intel/alder_lake.dtsi:452 */
			status = "okay";              /* in zephyr/dts/x86/intel/alder_lake.dtsi:454 */
		};

		/* node '/soc/mfd@70' defined in zephyr/dts/x86/intel/alder_lake.dtsi:457 */
		mfd: mfd@70 {
			compatible = "motorola,mc146818-mfd";          /* in zephyr/dts/x86/intel/alder_lake.dtsi:458 */
			reg = < 0x70 0x1 0x71 0x1 0x72 0x1 0x73 0x1 >; /* in zephyr/dts/x86/intel/alder_lake.dtsi:459 */
			status = "okay";                               /* in zephyr/dts/x86/intel/alder_lake.dtsi:476 */

			/* node '/soc/mfd@70/rtc' defined in zephyr/dts/x86/intel/alder_lake.dtsi:461 */
			rtc: counter: rtc {
				compatible = "motorola,mc146818"; /* in zephyr/dts/x86/intel/alder_lake.dtsi:462 */
				interrupts = < 0x8 0x100 0x3 >;   /* in zephyr/dts/x86/intel/alder_lake.dtsi:463 */
				interrupt-parent = < &intc >;     /* in zephyr/dts/x86/intel/alder_lake.dtsi:464 */
				alarms-count = < 0x1 >;           /* in zephyr/dts/x86/intel/alder_lake.dtsi:465 */
				status = "okay";                  /* in zephyr/dts/x86/intel/alder_lake.dtsi:467 */
			};

			/* node '/soc/mfd@70/bbram' defined in zephyr/dts/x86/intel/alder_lake.dtsi:470 */
			bbram: bbram {
				compatible = "motorola,mc146818-bbram"; /* in zephyr/dts/x86/intel/alder_lake.dtsi:471 */
				size = < 0xf1 >;                        /* in zephyr/dts/x86/intel/alder_lake.dtsi:472 */
				status = "okay";                        /* in zephyr/dts/x86/intel/alder_lake.dtsi:473 */
			};
		};

		/* node '/soc/tco_wdt@400' defined in zephyr/dts/x86/intel/alder_lake.dtsi:479 */
		tco_wdt: tco_wdt@400 {
			compatible = "intel,tco-wdt"; /* in zephyr/dts/x86/intel/alder_lake.dtsi:480 */
			reg = < 0x400 0x20 >;         /* in zephyr/dts/x86/intel/alder_lake.dtsi:481 */
			status = "disabled";          /* in zephyr/dts/x86/intel/alder_lake.dtsi:482 */
		};

		/* node '/soc/pwm0@fd6d0000' defined in zephyr/dts/x86/intel/alder_lake.dtsi:485 */
		pwm0: pwm0@fd6d0000 {
			compatible = "intel,blinky-pwm"; /* in zephyr/dts/x86/intel/alder_lake.dtsi:486 */
			reg = < 0xfd6d0000 0x400 >;      /* in zephyr/dts/x86/intel/alder_lake.dtsi:487 */
			reg-offset = < 0x204 >;          /* in zephyr/dts/x86/intel/alder_lake.dtsi:488 */
			clock-frequency = < 0x8000 >;    /* in zephyr/dts/x86/intel/alder_lake.dtsi:489 */
			max-pins = < 0x1 >;              /* in zephyr/dts/x86/intel/alder_lake.dtsi:490 */
			#pwm-cells = < 0x2 >;            /* in zephyr/dts/x86/intel/alder_lake.dtsi:491 */
			status = "okay";                 /* in zephyr/dts/x86/intel/alder_lake.dtsi:492 */
		};
	};
};
